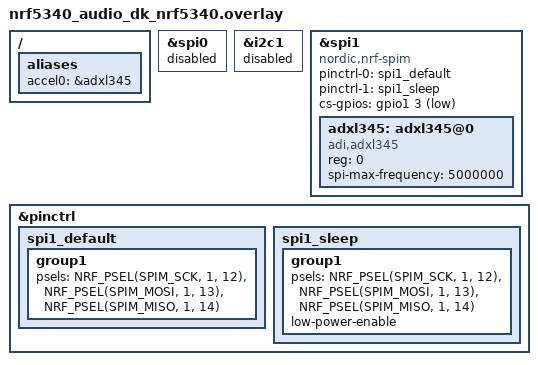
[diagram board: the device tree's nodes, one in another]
&spi0 {	status = "disabled";};
&i2c1 {	status = "disabled";};

&spi1 {
    compatible = "nordic,nrf-spim";
    status = "okay";
    pinctrl-0 = <&spi1_default>;
    pinctrl-1 = <&spi1_sleep>;
    pinctrl-names = "default", "sleep";
    cs-gpios = <&gpio1 3 GPIO_ACTIVE_LOW>;

    adxl345: adxl345@0 {
    compatible = "adi,adxl345";
    reg = <0>;
    spi-max-frequency = <5000000>;
    }; 
};
/* STEP 2.2 - Change the pin configuration */

/ {
    aliases {
            accel0 = &adxl345;
        };
    };

&pinctrl {
    spi1_default: spi1_default {
        group1 {
            psels = <NRF_PSEL(SPIM_SCK, 1, 12)>,    // SCK
                    <NRF_PSEL(SPIM_MOSI, 1, 13)>,   // SDA
                    <NRF_PSEL(SPIM_MISO, 1, 14)>;   // SDO
        };
    };
    spi1_sleep: spi1_sleep {
        group1 {
            psels = <NRF_PSEL(SPIM_SCK, 1, 12)>,
                    <NRF_PSEL(SPIM_MOSI, 1, 13)>,
                    <NRF_PSEL(SPIM_MISO, 1, 14)>;
            low-power-enable;
        };
    };
};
